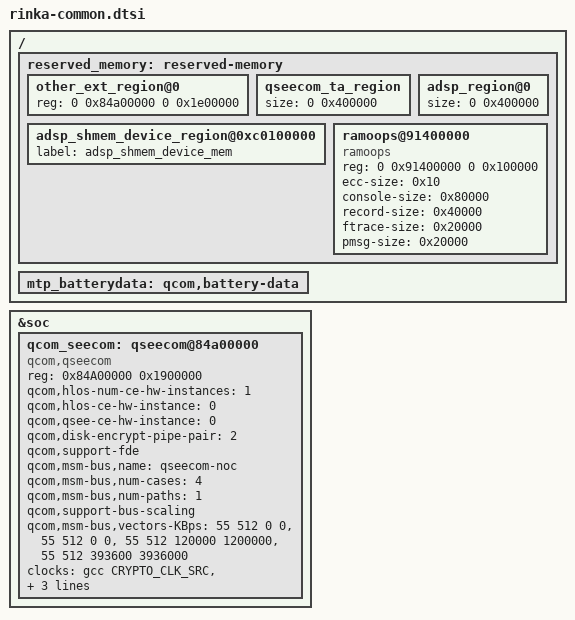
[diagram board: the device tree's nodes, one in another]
/ {
	reserved_memory: reserved-memory {

		other_ext_region@0 {

			/delete-property/ reg;

			reg = <0 0x84a00000 0 0x1e00000>;
		};

		qseecom_ta_region {

			/delete-property/ size;

			size = <0 0x400000>;

		};

		adsp_region@0 {

			/delete-property/ size;

			size = <0 0x400000>;
		};

		adsp_shmem_device_region@0xc0100000 {

			label = "adsp_shmem_device_mem";
		};

		ramoops@91400000 {
			compatible = "ramoops";
			reg = <0 0x91400000 0 0x100000>;
			ecc-size = <0x10>;
			console-size = <0x80000>;
			record-size = <0x40000>;
			ftrace-size = <0x20000>;
			pmsg-size = <0x20000>;
		};
	};

	mtp_batterydata: qcom,battery-data {
		#include "qg-batterydata-V430-4950mah-300k.dtsi"
	};

};

&soc {

	qcom_seecom: qseecom@84a00000 {
		compatible = "qcom,qseecom";
		reg = <0x84A00000 0x1900000>;
		reg-names = "secapp-region";
		qcom,hlos-num-ce-hw-instances = <1>;
		qcom,hlos-ce-hw-instance = <0>;
		qcom,qsee-ce-hw-instance = <0>;
		qcom,disk-encrypt-pipe-pair = <2>;
		qcom,support-fde;
		qcom,msm-bus,name = "qseecom-noc";
		qcom,msm-bus,num-cases = <4>;
		qcom,msm-bus,num-paths = <1>;
		qcom,support-bus-scaling;
		qcom,msm-bus,vectors-KBps =
			<55 512 0 0>,
			<55 512 0 0>,
			<55 512 120000 1200000>,
			<55 512 393600 3936000>;
		clocks = <&gcc CRYPTO_CLK_SRC>,
			<&gcc GCC_CRYPTO_CLK>,
			<&gcc GCC_CRYPTO_AHB_CLK>,
			<&gcc GCC_CRYPTO_AXI_CLK>;
		clock-names = "core_clk_src", "core_clk",
				"iface_clk", "bus_clk";
		qcom,ce-opp-freq = <100000000>;

		/delete-property/ qcom,appsbl-qseecom-support;

	};

	/delete-node/ qseecom@85b00000;

};
